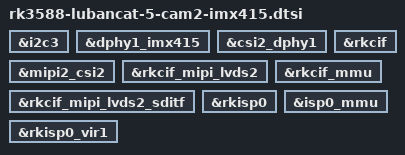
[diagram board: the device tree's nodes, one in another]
&i2c3 {
	status = "okay";
};

&dphy1_imx415 {
	status = "okay";
};

&csi2_dphy1 {
	status = "okay";
};

&mipi2_csi2 {
	status = "okay";
};

&rkcif {
	status = "okay";
};

&rkcif_mipi_lvds2 {
	status = "okay";
};

&rkcif_mipi_lvds2_sditf {
	status = "okay";
};

&rkcif_mmu {
	status = "okay";
};

&rkisp0 {
	status = "okay";
};

&isp0_mmu {
	status = "okay";
};

&rkisp0_vir1 {
	status = "okay";
};

